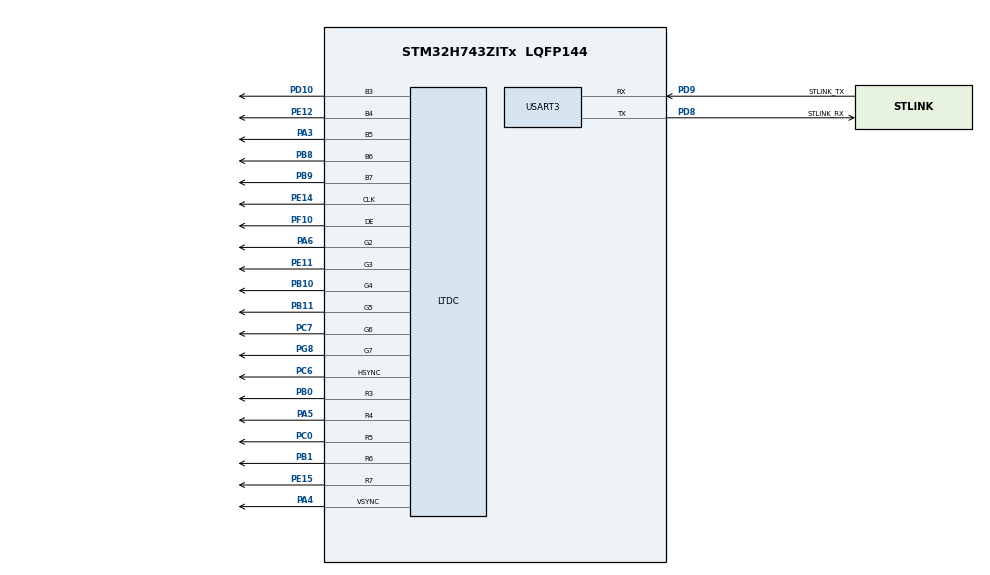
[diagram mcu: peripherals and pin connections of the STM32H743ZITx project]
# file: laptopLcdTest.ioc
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LTDC.ActiveH=800
LTDC.ActiveW=1280
LTDC.Alpha0_L0=0
LTDC.Alpha_L0=255
LTDC.BlendingFactor1_L0=LTDC_BLENDING_FACTOR1_PAxCA
LTDC.BlendingFactor2_L0=LTDC_BLENDING_FACTOR2_CA
LTDC.Blue=255
LTDC.Blue_L0=0
LTDC.DEPolarity=LTDC_DEPOLARITY_AL
LTDC.HBP=100
LTDC.HFP=10
LTDC.HSPolarity=LTDC_HSPOLARITY_AL
LTDC.HSync=40
LTDC.Layers=0
LTDC.PCPolarity=LTDC_PCPOLARITY_IPC
LTDC.PixelFormat_L0=LTDC_PIXEL_FORMAT_RGB565
LTDC.Red=255
LTDC.VBP=14
LTDC.VFP=3
LTDC.VSPolarity=LTDC_VSPOLARITY_AL
LTDC.VSync=16
LTDC.WindowX0_L0=10
LTDC.WindowX1_L0=364
LTDC.WindowY0_L0=10
LTDC.WindowY1_L0=364
Mcu.Family=STM32H7
Mcu.Name=STM32H743ZITx
Mcu.Package=LQFP144
NVIC.PriorityGroup=NVIC_PRIORITYGROUP_4
PA3.GPIO_Speed=GPIO_SPEED_FREQ_VERY_HIGH
PA3.Mode=RGB565
PA3.Signal=LTDC_B5
PA4.GPIO_Speed=GPIO_SPEED_FREQ_VERY_HIGH
PA4.Mode=RGB565
PA4.Signal=LTDC_VSYNC
PA5.GPIO_Speed=GPIO_SPEED_FREQ_VERY_HIGH
PA5.Mode=RGB565
PA5.Signal=LTDC_R4
PA6.GPIO_Speed=GPIO_SPEED_FREQ_VERY_HIGH
PA6.Mode=RGB565
PA6.Signal=LTDC_G2
PB0.GPIO_Speed=GPIO_SPEED_FREQ_VERY_HIGH
PB0.Mode=RGB565
PB0.Signal=LTDC_R3
PB1.GPIO_Speed=GPIO_SPEED_FREQ_VERY_HIGH
PB1.Mode=RGB565
PB1.Signal=LTDC_R6
PB10.GPIO_Speed=GPIO_SPEED_FREQ_VERY_HIGH
PB10.Mode=RGB565
PB10.Signal=LTDC_G4
PB11.GPIO_Speed=GPIO_SPEED_FREQ_VERY_HIGH
PB11.Mode=RGB565
PB11.Signal=LTDC_G5
PB8.GPIO_Speed=GPIO_SPEED_FREQ_VERY_HIGH
PB8.Mode=RGB565
PB8.Signal=LTDC_B6
PB9.GPIO_Speed=GPIO_SPEED_FREQ_VERY_HIGH
PB9.Mode=RGB565
PB9.Signal=LTDC_B7
PC0.GPIO_Speed=GPIO_SPEED_FREQ_VERY_HIGH
PC0.Mode=RGB565
PC0.Signal=LTDC_R5
PC14-OSC32_IN\ (OSC32_IN).Mode=LSE-External-Oscillator
PC14-OSC32_IN\ (OSC32_IN).Signal=RCC_OSC32_IN
PC15-OSC32_OUT\ (OSC32_OUT).Mode=LSE-External-Oscillator
PC15-OSC32_OUT\ (OSC32_OUT).Signal=RCC_OSC32_OUT
PC6.GPIO_Speed=GPIO_SPEED_FREQ_VERY_HIGH
PC6.Mode=RGB565
PC6.Signal=LTDC_HSYNC
PC7.GPIO_Speed=GPIO_SPEED_FREQ_VERY_HIGH
PC7.Mode=RGB565
PC7.Signal=LTDC_G6
PD10.GPIO_Speed=GPIO_SPEED_FREQ_VERY_HIGH
PD10.Mode=RGB565
PD10.Signal=LTDC_B3
PD8.GPIO_Label=STLINK_RX
PD8.Mode=Asynchronous
PD8.Signal=USART3_TX
PD9.GPIO_Label=STLINK_TX
PD9.Mode=Asynchronous
PD9.Signal=USART3_RX
PE11.GPIO_Speed=GPIO_SPEED_FREQ_VERY_HIGH
PE11.Mode=RGB565
PE11.Signal=LTDC_G3
PE12.GPIO_Speed=GPIO_SPEED_FREQ_VERY_HIGH
PE12.Mode=RGB565
PE12.Signal=LTDC_B4
PE14.GPIO_Speed=GPIO_SPEED_FREQ_VERY_HIGH
PE14.Mode=RGB565
PE14.Signal=LTDC_CLK
PE15.GPIO_Speed=GPIO_SPEED_FREQ_VERY_HIGH
PE15.Mode=RGB565
PE15.Signal=LTDC_R7
PF10.GPIO_Speed=GPIO_SPEED_FREQ_VERY_HIGH
PF10.Mode=RGB565
PF10.Signal=LTDC_DE
PG8.Mode=RGB565
PG8.Signal=LTDC_G7
PH0-OSC_IN\ (PH0).Mode=HSE-External-Clock-Source
PH0-OSC_IN\ (PH0).Signal=RCC_OSC_IN
PH1-OSC_OUT\ (PH1).Signal=RCC_OSC_OUT
ProjectManager.HeapSize=0x200
ProjectManager.StackSize=0x400
ProjectManager.TargetToolchain=STM32CubeIDE
RCC.ADCFreq_Value=16125000
RCC.APB1Freq_Value=60000000
RCC.APB2Freq_Value=120000000
RCC.APB3Freq_Value=120000000
RCC.APB4Freq_Value=120000000
RCC.CortexFreq_Value=120000000
RCC.D2PPRE1=RCC_APB1_DIV2
RCC.DIVM1=1
RCC.DIVM3=1
RCC.DIVN1=30
RCC.DIVN3=18
RCC.DIVQ1=4
RCC.HCLKFreq_Value=120000000
RCC.HSE_VALUE=8000000
RCC.PLL2FRACN=0
RCC.PLL3FRACN=6144
RCC.PLLFRACN=0
RCC.PLLSourceVirtual=RCC_PLLSOURCE_HSE
RCC.PWR_Regulator_Voltage_Scale=PWR_REGULATOR_VOLTAGE_SCALE2
RCC.SYSCLKFreq_VALUE=120000000
RCC.SYSCLKSource=RCC_SYSCLKSOURCE_PLLCLK
RCC.USBFreq_Value=60000000
USART3.VirtualMode-Asynchronous=VM_ASYNC
board=NUCLEO-H743ZI2

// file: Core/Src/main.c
/* USER CODE BEGIN Header */
/**
  ******************************************************************************
  * @file           : main.c
  * @brief          : Main program body
  ******************************************************************************
  * @attention
  *
  * Copyright (c) 2024 STMicroelectronics.
  * All rights reserved.
  *
  * This software is licensed under terms that can be found in the LICENSE file
  * in the root directory of this software component.
  * If no LICENSE file comes with this software, it is provided AS-IS.
  *
  ******************************************************************************
  */
/* USER CODE END Header */
#include "main.h"

/* USER CODE BEGIN Includes */
#include "img4.h"
/* USER CODE END Includes */

LTDC_HandleTypeDef hltdc;

UART_HandleTypeDef huart3;

void SystemClock_Config(void);
static void MX_GPIO_Init(void);
static void MX_USART3_UART_Init(void);
static void MX_LTDC_Init(void);
/* USER CODE BEGIN PFP */
uint8_t buffer[400000];
/* USER CODE END PFP */

int main(void)
{

  /* MCU Configuration--------------------------------------------------------*/

  /* Reset of all peripherals, Initializes the Flash interface and the Systick. */
  HAL_Init();

  /* Configure the system clock */
  SystemClock_Config();

  /* Initialize all configured peripherals */
  MX_GPIO_Init();
  MX_USART3_UART_Init();
  MX_LTDC_Init();
  /* USER CODE BEGIN 2 */
  uint16_t *_fbPtr = (uint16_t*)buffer;

  for (int i = 0; i < (354*354); i++)
  {
	  _fbPtr[i] = image4[i];
  }

  HAL_LTDC_SetAddress(&hltdc, buffer, 0);

  /* USER CODE END 2 */

  /* Infinite loop */
  /* USER CODE BEGIN WHILE */
  while (1)
  {
	  char okString[] = "I'm ok!";
	  HAL_UART_Transmit(&huart3, okString, sizeof(okString), HAL_MAX_DELAY);
	  HAL_Delay(1000ULL);
    /* USER CODE END WHILE */

  }
}

void SystemClock_Config(void)
{
  RCC_OscInitTypeDef RCC_OscInitStruct = {0};
  RCC_ClkInitTypeDef RCC_ClkInitStruct = {0};

  /** Supply configuration update enable
  */
  HAL_PWREx_ConfigSupply(PWR_LDO_SUPPLY);

  /** Configure the main internal regulator output voltage
  */
  __HAL_PWR_VOLTAGESCALING_CONFIG(PWR_REGULATOR_VOLTAGE_SCALE2);

  while(!__HAL_PWR_GET_FLAG(PWR_FLAG_VOSRDY)) {}

  /** Initializes the RCC Oscillators according to the specified parameters
  * in the RCC_OscInitTypeDef structure.
  */
  RCC_OscInitStruct.OscillatorType = RCC_OSCILLATORTYPE_HSE;
  RCC_OscInitStruct.HSEState = RCC_HSE_BYPASS;
  RCC_OscInitStruct.PLL.PLLState = RCC_PLL_ON;
  RCC_OscInitStruct.PLL.PLLSource = RCC_PLLSOURCE_HSE;
  RCC_OscInitStruct.PLL.PLLM = 1;
  RCC_OscInitStruct.PLL.PLLN = 30;
  RCC_OscInitStruct.PLL.PLLP = 2;
  RCC_OscInitStruct.PLL.PLLQ = 4;
  RCC_OscInitStruct.PLL.PLLR = 2;
  RCC_OscInitStruct.PLL.PLLRGE = RCC_PLL1VCIRANGE_3;
  RCC_OscInitStruct.PLL.PLLVCOSEL = RCC_PLL1VCOWIDE;
  RCC_OscInitStruct.PLL.PLLFRACN = 0;
  if (HAL_RCC_OscConfig(&RCC_OscInitStruct) != HAL_OK)
  {
    Error_Handler();
  }

  /** Initializes the CPU, AHB and APB buses clocks
  */
  RCC_ClkInitStruct.ClockType = RCC_CLOCKTYPE_HCLK|RCC_CLOCKTYPE_SYSCLK
                              |RCC_CLOCKTYPE_PCLK1|RCC_CLOCKTYPE_PCLK2
                              |RCC_CLOCKTYPE_D3PCLK1|RCC_CLOCKTYPE_D1PCLK1;
  RCC_ClkInitStruct.SYSCLKSource = RCC_SYSCLKSOURCE_PLLCLK;
  RCC_ClkInitStruct.SYSCLKDivider = RCC_SYSCLK_DIV1;
  RCC_ClkInitStruct.AHBCLKDivider = RCC_HCLK_DIV1;
  RCC_ClkInitStruct.APB3CLKDivider = RCC_APB3_DIV1;
  RCC_ClkInitStruct.APB1CLKDivider = RCC_APB1_DIV2;
  RCC_ClkInitStruct.APB2CLKDivider = RCC_APB2_DIV1;
  RCC_ClkInitStruct.APB4CLKDivider = RCC_APB4_DIV1;

  if (HAL_RCC_ClockConfig(&RCC_ClkInitStruct, FLASH_LATENCY_2) != HAL_OK)
  {
    Error_Handler();
  }
}

static void MX_LTDC_Init(void)
{

  LTDC_LayerCfgTypeDef pLayerCfg = {0};

  hltdc.Instance = LTDC;
  hltdc.Init.HSPolarity = LTDC_HSPOLARITY_AL;
  hltdc.Init.VSPolarity = LTDC_VSPOLARITY_AL;
  hltdc.Init.DEPolarity = LTDC_DEPOLARITY_AL;
  hltdc.Init.PCPolarity = LTDC_PCPOLARITY_IPC;
  hltdc.Init.HorizontalSync = 39;
  hltdc.Init.VerticalSync = 15;
  hltdc.Init.AccumulatedHBP = 139;
  hltdc.Init.AccumulatedVBP = 29;
  hltdc.Init.AccumulatedActiveW = 1419;
  hltdc.Init.AccumulatedActiveH = 829;
  hltdc.Init.TotalWidth = 1429;
  hltdc.Init.TotalHeigh = 832;
  hltdc.Init.Backcolor.Blue = 255;
  hltdc.Init.Backcolor.Green = 0;
  hltdc.Init.Backcolor.Red = 255;
  if (HAL_LTDC_Init(&hltdc) != HAL_OK)
  {
    Error_Handler();
  }
  pLayerCfg.WindowX0 = 10;
  pLayerCfg.WindowX1 = 364;
  pLayerCfg.WindowY0 = 10;
  pLayerCfg.WindowY1 = 364;
  pLayerCfg.PixelFormat = LTDC_PIXEL_FORMAT_RGB565;
  pLayerCfg.Alpha = 255;
  pLayerCfg.Alpha0 = 0;
  pLayerCfg.BlendingFactor1 = LTDC_BLENDING_FACTOR1_PAxCA;
  pLayerCfg.BlendingFactor2 = LTDC_BLENDING_FACTOR2_CA;
  pLayerCfg.FBStartAdress = 0;
  pLayerCfg.ImageWidth = 354;
  pLayerCfg.ImageHeight = 354;
  pLayerCfg.Backcolor.Blue = 0;
  pLayerCfg.Backcolor.Green = 0;
  pLayerCfg.Backcolor.Red = 0;
  if (HAL_LTDC_ConfigLayer(&hltdc, &pLayerCfg, 0) != HAL_OK)
  {
    Error_Handler();
  }

}

static void MX_USART3_UART_Init(void)
{

  huart3.Instance = USART3;
  huart3.Init.BaudRate = 115200;
  huart3.Init.WordLength = UART_WORDLENGTH_8B;
  huart3.Init.StopBits = UART_STOPBITS_1;
  huart3.Init.Parity = UART_PARITY_NONE;
  huart3.Init.Mode = UART_MODE_TX_RX;
  huart3.Init.HwFlowCtl = UART_HWCONTROL_NONE;
  huart3.Init.OverSampling = UART_OVERSAMPLING_16;
  huart3.Init.OneBitSampling = UART_ONE_BIT_SAMPLE_DISABLE;
  huart3.Init.ClockPrescaler = UART_PRESCALER_DIV1;
  huart3.AdvancedInit.AdvFeatureInit = UART_ADVFEATURE_NO_INIT;
  if (HAL_UART_Init(&huart3) != HAL_OK)
  {
    Error_Handler();
  }
  if (HAL_UARTEx_SetTxFifoThreshold(&huart3, UART_TXFIFO_THRESHOLD_1_8) != HAL_OK)
  {
    Error_Handler();
  }
  if (HAL_UARTEx_SetRxFifoThreshold(&huart3, UART_RXFIFO_THRESHOLD_1_8) != HAL_OK)
  {
    Error_Handler();
  }
  if (HAL_UARTEx_DisableFifoMode(&huart3) != HAL_OK)
  {
    Error_Handler();
  }

}

static void MX_GPIO_Init(void)
{

  /* GPIO Ports Clock Enable */
  __HAL_RCC_GPIOC_CLK_ENABLE();
  __HAL_RCC_GPIOF_CLK_ENABLE();
  __HAL_RCC_GPIOH_CLK_ENABLE();
  __HAL_RCC_GPIOA_CLK_ENABLE();
  __HAL_RCC_GPIOB_CLK_ENABLE();
  __HAL_RCC_GPIOE_CLK_ENABLE();
  __HAL_RCC_GPIOD_CLK_ENABLE();
  __HAL_RCC_GPIOG_CLK_ENABLE();

}

void Error_Handler(void)
{
  __disable_irq();
  while (1)
  {
  }
}
